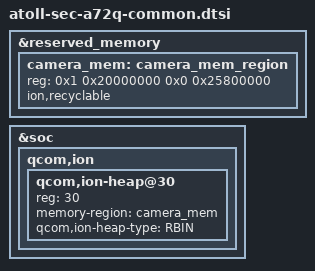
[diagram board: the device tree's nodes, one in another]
/* Copyright (c) 2020, The Linux Foundation. All rights reserved.
 *
 * This program is free software; you can redistribute it and/or modify
 * it under the terms of the GNU General Public License version 2 and
 * only version 2 as published by the Free Software Foundation.
 *
 * This program is distributed in the hope that it will be useful,
 * but WITHOUT ANY WARRANTY; without even the implied warranty of
 * MERCHANTABILITY or FITNESS FOR A PARTICULAR PURPOSE.  See the
 * GNU General Public License for more details.
 */

&reserved_memory {
	camera_mem: camera_mem_region {
		reg = <0x1 0x20000000 0x0 0x25800000>;
		ion,recyclable;
	};
};

&soc {
	qcom,ion {
		qcom,ion-heap@30 { /* CAMERA HEAP  */
			reg = <30>;
			memory-region = <&camera_mem>;
			qcom,ion-heap-type = "RBIN";
		};
	};
};
